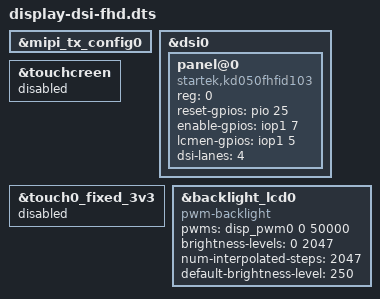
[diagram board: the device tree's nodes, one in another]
/dts-v1/;
/plugin/;

/ {
	fragment@0 {
		target = <&mipi_tx_config0>;
		__overlay__ {
			status = "okay";
		};
	};

	fragment@1 {
		target = <&dsi0>;
		__overlay__ {
			status = "okay";
			panel@0 {
				compatible = "startek,kd050fhfid103";
				reg = <0>;
				/delete-property/ leden-gpios;
				reset-gpios = <&pio 25 0>;
				enable-gpios = <&iop1 7 0>;
				lcmen-gpios = <&iop1 5 0>;
				dsi-lanes = <4>;
				status = "okay";
			};
		};
	};

	fragment@2 {
		target = <&touchcreen>;
		__overlay__ {
			status = "disabled";
		};
	};

	fragment@3 {
		target = <&touch0_fixed_3v3>;
		__overlay__ {
			status = "disabled";
		};
	};

	fragment@4 {
		target = <&backlight_lcd0>;
		__overlay__ {
			compatible = "pwm-backlight";
			pwms = <&disp_pwm0 0 50000>;
			brightness-levels = <0 2047>;
			num-interpolated-steps = <2047>;
			default-brightness-level = <250>;
			status = "okay";
		};
	};
};
